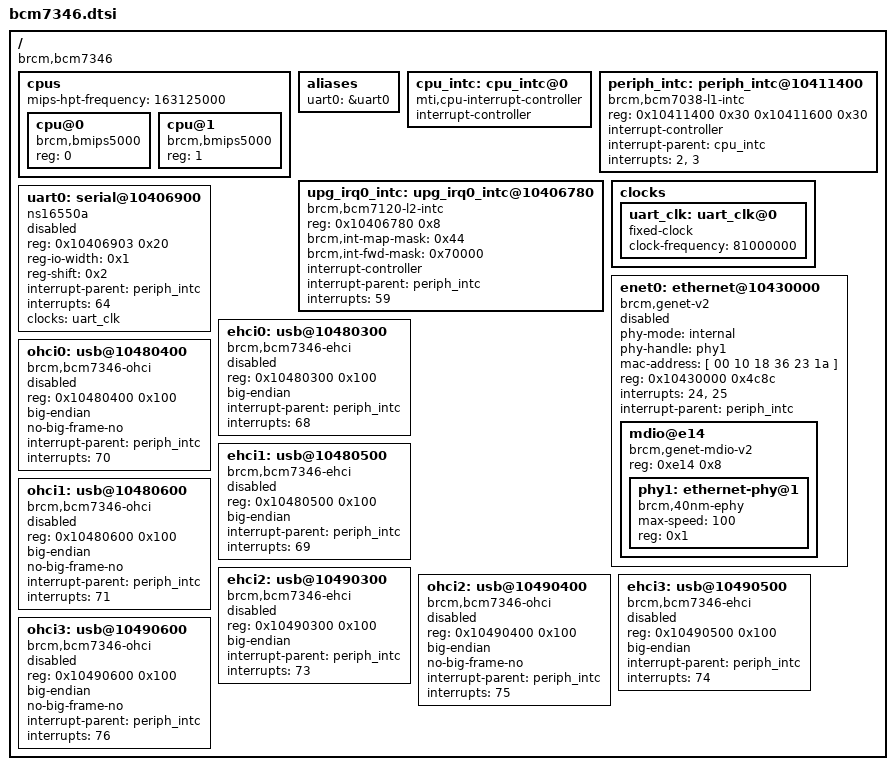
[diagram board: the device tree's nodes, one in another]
/ {
	#address-cells = <1>;
	#size-cells = <1>;
	compatible = "brcm,bcm7346";

	cpus {
		#address-cells = <1>;
		#size-cells = <0>;

		mips-hpt-frequency = <163125000>;

		cpu@0 {
			compatible = "brcm,bmips5000";
			device_type = "cpu";
			reg = <0>;
		};

		cpu@1 {
			compatible = "brcm,bmips5000";
			device_type = "cpu";
			reg = <1>;
		};
	};

	aliases {
		uart0 = &uart0;
	};

	cpu_intc: cpu_intc@0 {
		#address-cells = <0>;
		compatible = "mti,cpu-interrupt-controller";

		interrupt-controller;
		#interrupt-cells = <1>;
	};

	periph_intc: periph_intc@10411400 {
		compatible = "brcm,bcm7038-l1-intc";
		reg = <0x10411400 0x30 0x10411600 0x30>;

		interrupt-controller;
		#interrupt-cells = <1>;

		interrupt-parent = <&cpu_intc>;
		interrupts = <2>, <3>;
	};

	upg_irq0_intc: upg_irq0_intc@10406780 {
		compatible = "brcm,bcm7120-l2-intc";
		reg = <0x10406780 0x8>;

		brcm,int-map-mask = <0x44>;
		brcm,int-fwd-mask = <0x70000>;

		interrupt-controller;
		#interrupt-cells = <1>;

		interrupt-parent = <&periph_intc>;
		interrupts = <59>;
	};

	clocks {
		#address-cells = <1>;
		#size-cells = <0>;

		uart_clk: uart_clk@0 {
			compatible = "fixed-clock";
			#clock-cells = <0>;
			clock-frequency = <81000000>;
		};
	};

	uart0: serial@10406900 {
		compatible = "ns16550a";
		/* FIXME: need to use 0x10406900 for LE builds */
		reg = <0x10406903 0x20>;
		reg-io-width = <0x1>;
		reg-shift = <0x2>;
		interrupt-parent = <&periph_intc>;
		interrupts = <64>;
		clocks = <&uart_clk>;
		status = "disabled";
	};

	enet0: ethernet@10430000 {
		phy-mode = "internal";
		phy-handle = <&phy1>;
		mac-address = [ 00 10 18 36 23 1a ];
		compatible = "brcm,genet-v2";
		#address-cells = <0x1>;
		#size-cells = <0x1>;
		reg = <0x10430000 0x4c8c>;
		interrupts = <24>, <25>;
		interrupt-parent = <&periph_intc>;
		status = "disabled";

		mdio@e14 {
			compatible = "brcm,genet-mdio-v2";
			#address-cells = <0x1>;
			#size-cells = <0x0>;
			reg = <0xe14 0x8>;

			phy1: ethernet-phy@1 {
				max-speed = <100>;
				reg = <0x1>;
				compatible = "brcm,40nm-ephy",
					     "ethernet-phy-ieee802.3-c22";
			};
		};
	};

	ehci0: usb@10480300 {
		compatible = "brcm,bcm7346-ehci", "generic-ehci";
		reg = <0x10480300 0x100>;
		big-endian;
		interrupt-parent = <&periph_intc>;
		interrupts = <68>;
		status = "disabled";
	};

	ohci0: usb@10480400 {
		compatible = "brcm,bcm7346-ohci", "generic-ohci";
		reg = <0x10480400 0x100>;
		big-endian;
		no-big-frame-no;
		interrupt-parent = <&periph_intc>;
		interrupts = <70>;
		status = "disabled";
	};

	ehci1: usb@10480500 {
		compatible = "brcm,bcm7346-ehci", "generic-ehci";
		reg = <0x10480500 0x100>;
		big-endian;
		interrupt-parent = <&periph_intc>;
		interrupts = <69>;
		status = "disabled";
	};

	ohci1: usb@10480600 {
		compatible = "brcm,bcm7346-ohci", "generic-ohci";
		reg = <0x10480600 0x100>;
		big-endian;
		no-big-frame-no;
		interrupt-parent = <&periph_intc>;
		interrupts = <71>;
		status = "disabled";
	};

	ehci2: usb@10490300 {
		compatible = "brcm,bcm7346-ehci", "generic-ehci";
		reg = <0x10490300 0x100>;
		big-endian;
		interrupt-parent = <&periph_intc>;
		interrupts = <73>;
		status = "disabled";
	};

	ohci2: usb@10490400 {
		compatible = "brcm,bcm7346-ohci", "generic-ohci";
		reg = <0x10490400 0x100>;
		big-endian;
		no-big-frame-no;
		interrupt-parent = <&periph_intc>;
		interrupts = <75>;
		status = "disabled";
	};

	ehci3: usb@10490500 {
		compatible = "brcm,bcm7346-ehci", "generic-ehci";
		reg = <0x10490500 0x100>;
		big-endian;
		interrupt-parent = <&periph_intc>;
		interrupts = <74>;
		status = "disabled";
	};

	ohci3: usb@10490600 {
		compatible = "brcm,bcm7346-ohci", "generic-ohci";
		reg = <0x10490600 0x100>;
		big-endian;
		no-big-frame-no;
		interrupt-parent = <&periph_intc>;
		interrupts = <76>;
		status = "disabled";
	};
};
